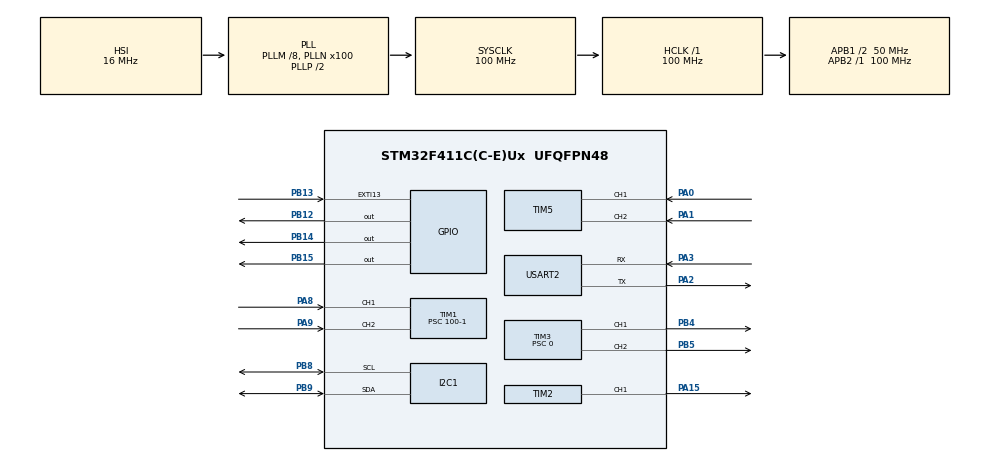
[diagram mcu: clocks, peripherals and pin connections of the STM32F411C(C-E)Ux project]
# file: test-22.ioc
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Mcu.Family=STM32F4
Mcu.Name=STM32F411C(C-E)Ux
Mcu.Package=UFQFPN48
NVIC.EXTI15_10_IRQn=true\:0\:0\:false\:false\:true\:true\:true\:true
NVIC.PriorityGroup=NVIC_PRIORITYGROUP_4
NVIC.TIM1_BRK_TIM9_IRQn=true\:0\:0\:false\:false\:true\:true\:true\:true
NVIC.TIM1_CC_IRQn=true\:0\:0\:false\:false\:true\:true\:true\:true
NVIC.TIM1_TRG_COM_TIM11_IRQn=true\:0\:0\:false\:false\:true\:true\:true\:true
NVIC.TIM1_UP_TIM10_IRQn=true\:0\:0\:false\:false\:true\:true\:true\:true
NVIC.TIM5_IRQn=true\:0\:0\:false\:false\:true\:true\:true\:true
PA0-WKUP.Signal=S_TIM5_CH1
PA1.Signal=S_TIM5_CH2
PA13.Mode=Trace_Asynchronous_SW
PA13.Signal=SYS_JTMS-SWDIO
PA14.Mode=Trace_Asynchronous_SW
PA14.Signal=SYS_JTCK-SWCLK
PA15.Signal=S_TIM2_CH1_ETR
PA2.Mode=Asynchronous
PA2.Signal=USART2_TX
PA3.Mode=Asynchronous
PA3.Signal=USART2_RX
PA8.Signal=S_TIM1_CH1
PA9.Signal=S_TIM1_CH2
PB12.Signal=GPIO_Output
PB13.Signal=GPXTI13
PB14.Signal=GPIO_Output
PB15.Signal=GPIO_Output
PB3.Mode=Trace_Asynchronous_SW
PB3.Signal=SYS_JTDO-SWO
PB4.Signal=S_TIM3_CH1
PB5.Signal=S_TIM3_CH2
PB8.Mode=I2C
PB8.Signal=I2C1_SCL
PB9.Mode=I2C
PB9.Signal=I2C1_SDA
ProjectManager.HeapSize=0x200
ProjectManager.StackSize=0x400
ProjectManager.TargetToolchain=STM32CubeIDE
RCC.48MHZClocksFreq_Value=50000000
RCC.AHBFreq_Value=100000000
RCC.APB1CLKDivider=RCC_HCLK_DIV2
RCC.APB1Freq_Value=50000000
RCC.APB1TimFreq_Value=100000000
RCC.APB2Freq_Value=100000000
RCC.APB2TimFreq_Value=100000000
RCC.CortexFreq_Value=100000000
RCC.HCLKFreq_Value=100000000
RCC.HSE_VALUE=25000000
RCC.HSI_VALUE=16000000
RCC.LSE_VALUE=32768
RCC.PLLM=8
RCC.PLLN=100
RCC.SYSCLKFreq_VALUE=100000000
RCC.SYSCLKSource=RCC_SYSCLKSOURCE_PLLCLK
RCC.VCOOutputFreq_Value=200000000
SH.S_TIM1_CH1.0=TIM1_CH1,Input_Capture1_from_TI1
SH.S_TIM1_CH2.0=TIM1_CH2,Input_Capture2_from_TI2
SH.S_TIM2_CH1_ETR.0=TIM2_CH1,PWM Generation1 CH1
SH.S_TIM3_CH1.0=TIM3_CH1,PWM Generation1 CH1
SH.S_TIM3_CH2.0=TIM3_CH2,PWM Generation2 CH2
SH.S_TIM5_CH1.0=TIM5_CH1,Encoder_Interface
SH.S_TIM5_CH2.0=TIM5_CH2,Encoder_Interface
TIM1.Channel-Input_Capture1_from_TI1=TIM_CHANNEL_1
TIM1.Channel-Input_Capture2_from_TI2=TIM_CHANNEL_2
TIM1.ICPolarity_CH1=TIM_INPUTCHANNELPOLARITY_BOTHEDGE
TIM1.ICPolarity_CH2=TIM_INPUTCHANNELPOLARITY_BOTHEDGE
TIM1.Prescaler=100-1
TIM2.Channel-PWM\ Generation1\ CH1=TIM_CHANNEL_1
TIM2.Period=5000-1
TIM3.Channel-PWM\ Generation1\ CH1=TIM_CHANNEL_1
TIM3.Channel-PWM\ Generation2\ CH2=TIM_CHANNEL_2
TIM3.Period=5000-1
TIM3.Prescaler=0
TIM5.EncoderMode=TIM_ENCODERMODE_TI12
USART2.VirtualMode=VM_ASYNC
VP_TIM1_VS_ClockSourceINT.Mode=Internal
VP_TIM2_VS_ClockSourceINT.Mode=Internal
VP_TIM3_VS_ClockSourceINT.Mode=Internal
board=custom

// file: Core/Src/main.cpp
/* USER CODE BEGIN Header */
/**
  ******************************************************************************
  * @file           : main.c
  * @brief          : Main program body
  ******************************************************************************
  * @attention
  *
  * Copyright (c) 2024 STMicroelectronics.
  * All rights reserved.
  *
  * This software is licensed under terms that can be found in the LICENSE file
  * in the root directory of this software component.
  * If no LICENSE file comes with this software, it is provided AS-IS.
  *
  ******************************************************************************
  */
/* USER CODE END Header */
#include "main.h"

/* USER CODE BEGIN Includes */
#include <stdio.h>
#include "vl53l0x_api.h"
/* USER CODE END Includes */

I2C_HandleTypeDef hi2c1;

TIM_HandleTypeDef htim1;
TIM_HandleTypeDef htim2;
TIM_HandleTypeDef htim3;
TIM_HandleTypeDef htim5;

UART_HandleTypeDef huart2;

void SystemClock_Config(void);
static void MX_GPIO_Init(void);
static void MX_USART2_UART_Init(void);
static void MX_TIM2_Init(void);
static void MX_TIM5_Init(void);
static void MX_TIM1_Init(void);
static void MX_TIM3_Init(void);
static void MX_I2C1_Init(void);

int main(void)
{

  /* MCU Configuration--------------------------------------------------------*/

  /* Reset of all peripherals, Initializes the Flash interface and the Systick. */
  HAL_Init();

  /* Configure the system clock */
  SystemClock_Config();

  /* Initialize all configured peripherals */
  MX_GPIO_Init();
  MX_USART2_UART_Init();
  MX_TIM2_Init();
  MX_TIM5_Init();
  MX_TIM1_Init();
  MX_TIM3_Init();
  MX_I2C1_Init();

  /* Infinite loop */
  while (1)
  {

  }
}

void SystemClock_Config(void)
{
  RCC_OscInitTypeDef RCC_OscInitStruct = {0};
  RCC_ClkInitTypeDef RCC_ClkInitStruct = {0};

  /** Configure the main internal regulator output voltage
  */
  __HAL_RCC_PWR_CLK_ENABLE();
  __HAL_PWR_VOLTAGESCALING_CONFIG(PWR_REGULATOR_VOLTAGE_SCALE1);

  /** Initializes the RCC Oscillators according to the specified parameters
  * in the RCC_OscInitTypeDef structure.
  */
  RCC_OscInitStruct.OscillatorType = RCC_OSCILLATORTYPE_HSI;
  RCC_OscInitStruct.HSIState = RCC_HSI_ON;
  RCC_OscInitStruct.HSICalibrationValue = RCC_HSICALIBRATION_DEFAULT;
  RCC_OscInitStruct.PLL.PLLState = RCC_PLL_ON;
  RCC_OscInitStruct.PLL.PLLSource = RCC_PLLSOURCE_HSI;
  RCC_OscInitStruct.PLL.PLLM = 8;
  RCC_OscInitStruct.PLL.PLLN = 100;
  RCC_OscInitStruct.PLL.PLLP = RCC_PLLP_DIV2;
  RCC_OscInitStruct.PLL.PLLQ = 4;
  if (HAL_RCC_OscConfig(&RCC_OscInitStruct) != HAL_OK)
  {
    Error_Handler();
  }

  /** Initializes the CPU, AHB and APB buses clocks
  */
  RCC_ClkInitStruct.ClockType = RCC_CLOCKTYPE_HCLK|RCC_CLOCKTYPE_SYSCLK
                              |RCC_CLOCKTYPE_PCLK1|RCC_CLOCKTYPE_PCLK2;
  RCC_ClkInitStruct.SYSCLKSource = RCC_SYSCLKSOURCE_PLLCLK;
  RCC_ClkInitStruct.AHBCLKDivider = RCC_SYSCLK_DIV1;
  RCC_ClkInitStruct.APB1CLKDivider = RCC_HCLK_DIV2;
  RCC_ClkInitStruct.APB2CLKDivider = RCC_HCLK_DIV1;

  if (HAL_RCC_ClockConfig(&RCC_ClkInitStruct, FLASH_LATENCY_3) != HAL_OK)
  {
    Error_Handler();
  }
}

static void MX_I2C1_Init(void)
{

  hi2c1.Instance = I2C1;
  hi2c1.Init.ClockSpeed = 100000;
  hi2c1.Init.DutyCycle = I2C_DUTYCYCLE_2;
  hi2c1.Init.OwnAddress1 = 0;
  hi2c1.Init.AddressingMode = I2C_ADDRESSINGMODE_7BIT;
  hi2c1.Init.DualAddressMode = I2C_DUALADDRESS_DISABLE;
  hi2c1.Init.OwnAddress2 = 0;
  hi2c1.Init.GeneralCallMode = I2C_GENERALCALL_DISABLE;
  hi2c1.Init.NoStretchMode = I2C_NOSTRETCH_DISABLE;
  if (HAL_I2C_Init(&hi2c1) != HAL_OK)
  {
    Error_Handler();
  }

}

static void MX_TIM1_Init(void)
{

  TIM_ClockConfigTypeDef sClockSourceConfig = {0};
  TIM_MasterConfigTypeDef sMasterConfig = {0};
  TIM_IC_InitTypeDef sConfigIC = {0};

  htim1.Instance = TIM1;
  htim1.Init.Prescaler = 100-1;
  htim1.Init.CounterMode = TIM_COUNTERMODE_UP;
  htim1.Init.Period = 65535;
  htim1.Init.ClockDivision = TIM_CLOCKDIVISION_DIV1;
  htim1.Init.RepetitionCounter = 0;
  htim1.Init.AutoReloadPreload = TIM_AUTORELOAD_PRELOAD_DISABLE;
  if (HAL_TIM_Base_Init(&htim1) != HAL_OK)
  {
    Error_Handler();
  }
  sClockSourceConfig.ClockSource = TIM_CLOCKSOURCE_INTERNAL;
  if (HAL_TIM_ConfigClockSource(&htim1, &sClockSourceConfig) != HAL_OK)
  {
    Error_Handler();
  }
  if (HAL_TIM_IC_Init(&htim1) != HAL_OK)
  {
    Error_Handler();
  }
  sMasterConfig.MasterOutputTrigger = TIM_TRGO_RESET;
  sMasterConfig.MasterSlaveMode = TIM_MASTERSLAVEMODE_DISABLE;
  if (HAL_TIMEx_MasterConfigSynchronization(&htim1, &sMasterConfig) != HAL_OK)
  {
    Error_Handler();
  }
  sConfigIC.ICPolarity = TIM_INPUTCHANNELPOLARITY_BOTHEDGE;
  sConfigIC.ICSelection = TIM_ICSELECTION_DIRECTTI;
  sConfigIC.ICPrescaler = TIM_ICPSC_DIV1;
  sConfigIC.ICFilter = 0;
  if (HAL_TIM_IC_ConfigChannel(&htim1, &sConfigIC, TIM_CHANNEL_1) != HAL_OK)
  {
    Error_Handler();
  }
  if (HAL_TIM_IC_ConfigChannel(&htim1, &sConfigIC, TIM_CHANNEL_2) != HAL_OK)
  {
    Error_Handler();
  }

}

static void MX_TIM2_Init(void)
{

  TIM_ClockConfigTypeDef sClockSourceConfig = {0};
  TIM_MasterConfigTypeDef sMasterConfig = {0};
  TIM_OC_InitTypeDef sConfigOC = {0};

  htim2.Instance = TIM2;
  htim2.Init.Prescaler = 0;
  htim2.Init.CounterMode = TIM_COUNTERMODE_UP;
  htim2.Init.Period = 5000-1;
  htim2.Init.ClockDivision = TIM_CLOCKDIVISION_DIV1;
  htim2.Init.AutoReloadPreload = TIM_AUTORELOAD_PRELOAD_DISABLE;
  if (HAL_TIM_Base_Init(&htim2) != HAL_OK)
  {
    Error_Handler();
  }
  sClockSourceConfig.ClockSource = TIM_CLOCKSOURCE_INTERNAL;
  if (HAL_TIM_ConfigClockSource(&htim2, &sClockSourceConfig) != HAL_OK)
  {
    Error_Handler();
  }
  if (HAL_TIM_PWM_Init(&htim2) != HAL_OK)
  {
    Error_Handler();
  }
  sMasterConfig.MasterOutputTrigger = TIM_TRGO_RESET;
  sMasterConfig.MasterSlaveMode = TIM_MASTERSLAVEMODE_DISABLE;
  if (HAL_TIMEx_MasterConfigSynchronization(&htim2, &sMasterConfig) != HAL_OK)
  {
    Error_Handler();
  }
  sConfigOC.OCMode = TIM_OCMODE_PWM1;
  sConfigOC.Pulse = 0;
  sConfigOC.OCPolarity = TIM_OCPOLARITY_HIGH;
  sConfigOC.OCFastMode = TIM_OCFAST_DISABLE;
  if (HAL_TIM_PWM_ConfigChannel(&htim2, &sConfigOC, TIM_CHANNEL_1) != HAL_OK)
  {
    Error_Handler();
  }
  HAL_TIM_MspPostInit(&htim2);

}

static void MX_TIM3_Init(void)
{

  TIM_ClockConfigTypeDef sClockSourceConfig = {0};
  TIM_MasterConfigTypeDef sMasterConfig = {0};
  TIM_OC_InitTypeDef sConfigOC = {0};

  htim3.Instance = TIM3;
  htim3.Init.Prescaler = 0;
  htim3.Init.CounterMode = TIM_COUNTERMODE_UP;
  htim3.Init.Period = 5000-1;
  htim3.Init.ClockDivision = TIM_CLOCKDIVISION_DIV1;
  htim3.Init.AutoReloadPreload = TIM_AUTORELOAD_PRELOAD_DISABLE;
  if (HAL_TIM_Base_Init(&htim3) != HAL_OK)
  {
    Error_Handler();
  }
  sClockSourceConfig.ClockSource = TIM_CLOCKSOURCE_INTERNAL;
  if (HAL_TIM_ConfigClockSource(&htim3, &sClockSourceConfig) != HAL_OK)
  {
    Error_Handler();
  }
  if (HAL_TIM_PWM_Init(&htim3) != HAL_OK)
  {
    Error_Handler();
  }
  sMasterConfig.MasterOutputTrigger = TIM_TRGO_RESET;
  sMasterConfig.MasterSlaveMode = TIM_MASTERSLAVEMODE_DISABLE;
  if (HAL_TIMEx_MasterConfigSynchronization(&htim3, &sMasterConfig) != HAL_OK)
  {
    Error_Handler();
  }
  sConfigOC.OCMode = TIM_OCMODE_PWM1;
  sConfigOC.Pulse = 0;
  sConfigOC.OCPolarity = TIM_OCPOLARITY_HIGH;
  sConfigOC.OCFastMode = TIM_OCFAST_DISABLE;
  if (HAL_TIM_PWM_ConfigChannel(&htim3, &sConfigOC, TIM_CHANNEL_1) != HAL_OK)
  {
    Error_Handler();
  }
  if (HAL_TIM_PWM_ConfigChannel(&htim3, &sConfigOC, TIM_CHANNEL_2) != HAL_OK)
  {
    Error_Handler();
  }
  HAL_TIM_MspPostInit(&htim3);

}

static void MX_TIM5_Init(void)
{

  TIM_Encoder_InitTypeDef sConfig = {0};
  TIM_MasterConfigTypeDef sMasterConfig = {0};

  htim5.Instance = TIM5;
  htim5.Init.Prescaler = 0;
  htim5.Init.CounterMode = TIM_COUNTERMODE_UP;
  htim5.Init.Period = 4294967295;
  htim5.Init.ClockDivision = TIM_CLOCKDIVISION_DIV1;
  htim5.Init.AutoReloadPreload = TIM_AUTORELOAD_PRELOAD_DISABLE;
  sConfig.EncoderMode = TIM_ENCODERMODE_TI12;
  sConfig.IC1Polarity = TIM_ICPOLARITY_RISING;
  sConfig.IC1Selection = TIM_ICSELECTION_DIRECTTI;
  sConfig.IC1Prescaler = TIM_ICPSC_DIV1;
  sConfig.IC1Filter = 0;
  sConfig.IC2Polarity = TIM_ICPOLARITY_RISING;
  sConfig.IC2Selection = TIM_ICSELECTION_DIRECTTI;
  sConfig.IC2Prescaler = TIM_ICPSC_DIV1;
  sConfig.IC2Filter = 0;
  if (HAL_TIM_Encoder_Init(&htim5, &sConfig) != HAL_OK)
  {
    Error_Handler();
  }
  sMasterConfig.MasterOutputTrigger = TIM_TRGO_RESET;
  sMasterConfig.MasterSlaveMode = TIM_MASTERSLAVEMODE_DISABLE;
  if (HAL_TIMEx_MasterConfigSynchronization(&htim5, &sMasterConfig) != HAL_OK)
  {
    Error_Handler();
  }

}

static void MX_USART2_UART_Init(void)
{

  huart2.Instance = USART2;
  huart2.Init.BaudRate = 115200;
  huart2.Init.WordLength = UART_WORDLENGTH_8B;
  huart2.Init.StopBits = UART_STOPBITS_1;
  huart2.Init.Parity = UART_PARITY_NONE;
  huart2.Init.Mode = UART_MODE_TX_RX;
  huart2.Init.HwFlowCtl = UART_HWCONTROL_NONE;
  huart2.Init.OverSampling = UART_OVERSAMPLING_16;
  if (HAL_UART_Init(&huart2) != HAL_OK)
  {
    Error_Handler();
  }

}

static void MX_GPIO_Init(void)
{
  GPIO_InitTypeDef GPIO_InitStruct = {0};

  /* GPIO Ports Clock Enable */
  __HAL_RCC_GPIOA_CLK_ENABLE();
  __HAL_RCC_GPIOB_CLK_ENABLE();

  /*Configure GPIO pin Output Level */
  HAL_GPIO_WritePin(GPIOB, GPIO_PIN_12|GPIO_PIN_14|GPIO_PIN_15, GPIO_PIN_RESET);

  /*Configure GPIO pins : PB12 PB14 PB15 */
  GPIO_InitStruct.Pin = GPIO_PIN_12|GPIO_PIN_14|GPIO_PIN_15;
  GPIO_InitStruct.Mode = GPIO_MODE_OUTPUT_PP;
  GPIO_InitStruct.Pull = GPIO_NOPULL;
  GPIO_InitStruct.Speed = GPIO_SPEED_FREQ_LOW;
  HAL_GPIO_Init(GPIOB, &GPIO_InitStruct);

  /*Configure GPIO pin : PB13 */
  GPIO_InitStruct.Pin = GPIO_PIN_13;
  GPIO_InitStruct.Mode = GPIO_MODE_IT_RISING;
  GPIO_InitStruct.Pull = GPIO_NOPULL;
  HAL_GPIO_Init(GPIOB, &GPIO_InitStruct);

  /* EXTI interrupt init*/
  HAL_NVIC_SetPriority(EXTI15_10_IRQn, 0, 0);
  HAL_NVIC_EnableIRQ(EXTI15_10_IRQn);

}

void Error_Handler(void)
{
  __disable_irq();
  while (1)
  {
  }
}
